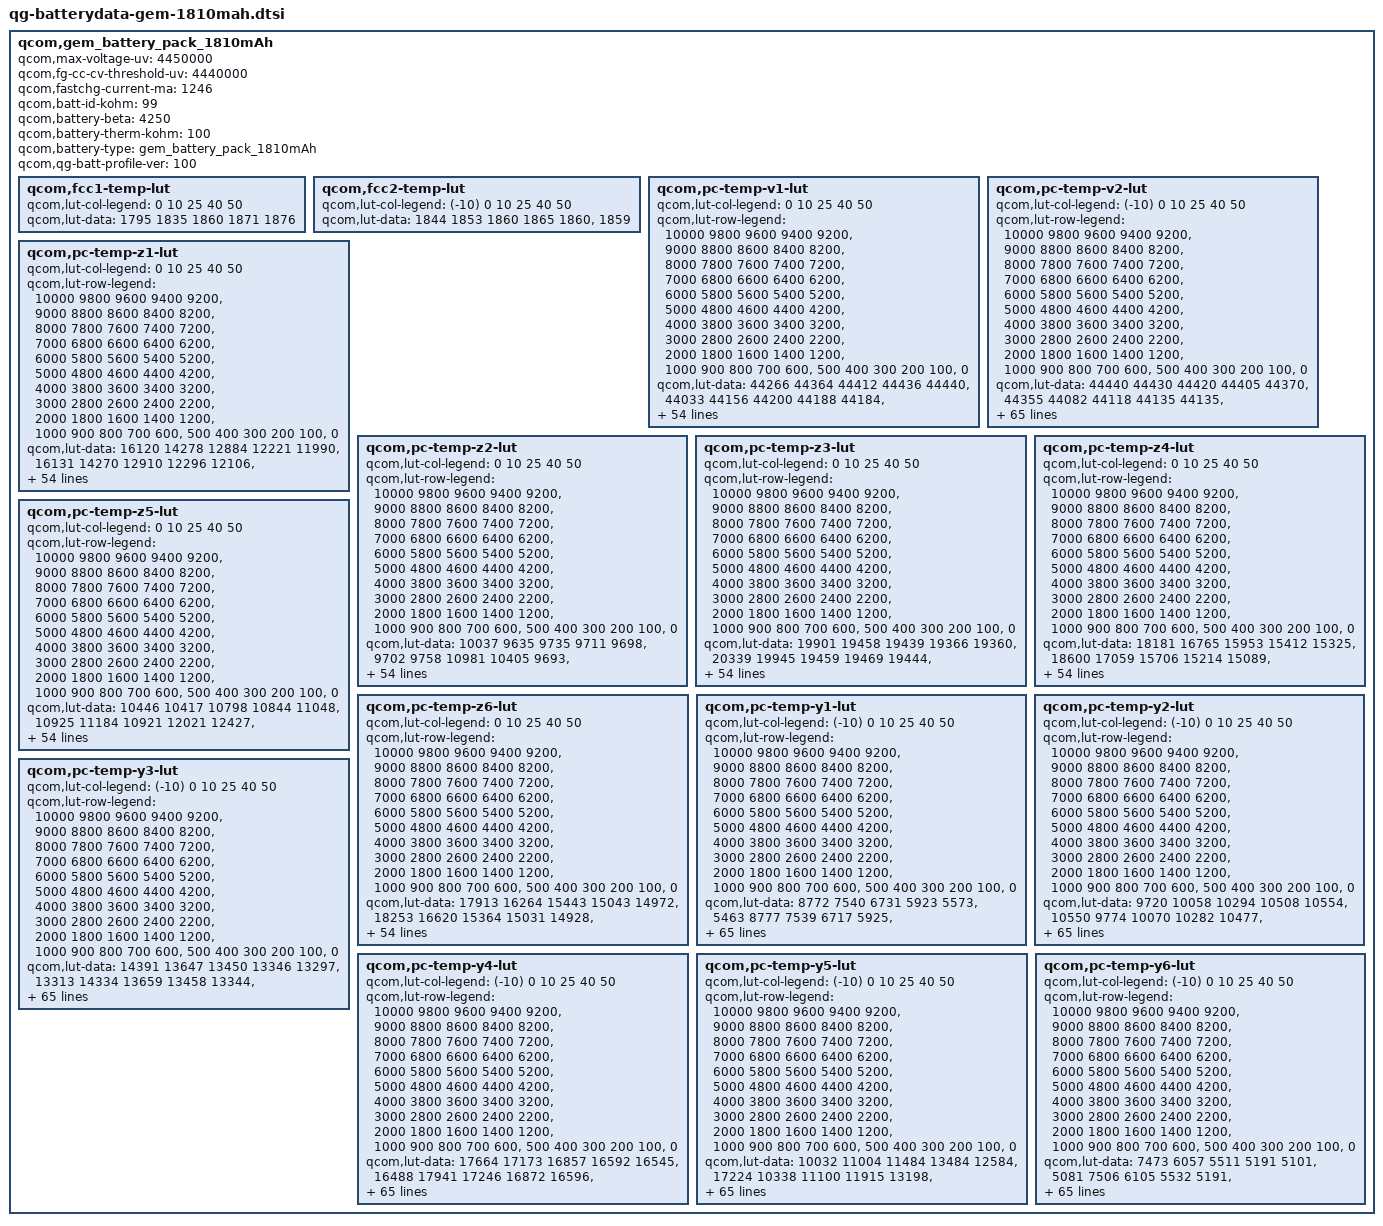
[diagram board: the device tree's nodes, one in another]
qcom,gem_battery_pack_1810mAh {
	qcom,max-voltage-uv = <4450000>;
	qcom,fg-cc-cv-threshold-uv = <4440000>;
	qcom,fastchg-current-ma = <1246>;
	qcom,batt-id-kohm = <99>;
	qcom,battery-beta = <4250>;
	qcom,battery-therm-kohm = <100>;
	qcom,battery-type = "gem_battery_pack_1810mAh";
	qcom,qg-batt-profile-ver = <100>;

	qcom,fcc1-temp-lut {
		qcom,lut-col-legend = <0 10 25 40 50>;
		qcom,lut-data = <1795 1835 1860 1871 1876>;
	};

	qcom,fcc2-temp-lut {
		qcom,lut-col-legend = <(-10) 0 10 25 40 50>;
		qcom,lut-data = <1844 1853 1860 1865 1860>,
			<1859>;
	};

	qcom,pc-temp-v1-lut {
		qcom,lut-col-legend = <0 10 25 40 50>;
		qcom,lut-row-legend = <10000 9800 9600 9400 9200>,
			<9000 8800 8600 8400 8200>,
			<8000 7800 7600 7400 7200>,
			<7000 6800 6600 6400 6200>,
			<6000 5800 5600 5400 5200>,
			<5000 4800 4600 4400 4200>,
			<4000 3800 3600 3400 3200>,
			<3000 2800 2600 2400 2200>,
			<2000 1800 1600 1400 1200>,
			<1000 900 800 700 600>,
			<500 400 300 200 100>,
			<0>;
		qcom,lut-data = <44266 44364 44412 44436 44440>,
			<44033 44156 44200 44188 44184>,
			<43803 43937 43983 43980 43968>,
			<43575 43713 43758 43763 43754>,
			<43350 43485 43530 43540 43536>,
			<43117 43251 43301 43315 43315>,
			<42874 43012 43067 43085 43088>,
			<42630 42765 42822 42847 42853>,
			<42387 42516 42568 42599 42606>,
			<42145 42269 42318 42350 42356>,
			<41909 42023 42072 42099 42109>,
			<41679 41784 41831 41852 41865>,
			<41454 41552 41591 41610 41624>,
			<41235 41325 41356 41375 41384>,
			<41021 41105 41131 41147 41154>,
			<40813 40892 40916 40926 40930>,
			<40611 40687 40709 40713 40716>,
			<40415 40488 40509 40511 40513>,
			<40226 40297 40316 40317 40321>,
			<40044 40117 40133 40130 40133>,
			<39870 39941 39962 39957 39958>,
			<39708 39754 39762 39769 39771>,
			<39549 39560 39472 39526 39539>,
			<39378 39355 39195 39271 39291>,
			<39202 39105 39037 39084 39099>,
			<39030 38875 38924 38938 38944>,
			<38849 38752 38814 38809 38808>,
			<38689 38673 38704 38691 38686>,
			<38585 38598 38599 38584 38576>,
			<38507 38519 38500 38482 38472>,
			<38442 38445 38408 38388 38377>,
			<38382 38373 38328 38303 38290>,
			<38331 38305 38257 38225 38209>,
			<38284 38245 38194 38154 38135>,
			<38243 38194 38140 38093 38070>,
			<38204 38148 38090 38038 38009>,
			<38169 38107 38042 37977 37938>,
			<38132 38069 37996 37913 37855>,
			<38077 38015 37937 37840 37768>,
			<37998 37926 37846 37753 37679>,
			<37903 37819 37735 37652 37582>,
			<37789 37705 37619 37537 37469>,
			<37654 37574 37488 37403 37336>,
			<37485 37413 37328 37247 37178>,
			<37327 37251 37176 37098 37031>,
			<37205 37143 37073 37004 36946>,
			<37182 37109 37051 36984 36923>,
			<37144 37086 37032 36967 36907>,
			<37109 37063 37014 36948 36891>,
			<37059 37018 36966 36887 36815>,
			<36871 36801 36720 36614 36524>,
			<36426 36362 36283 36170 36077>,
			<35839 35770 35703 35591 35497>,
			<35026 34940 34909 34800 34704>,
			<33654 33600 33657 33571 33473>,
			<30000 30000 30000 30000 30000>;
	};

	qcom,pc-temp-v2-lut {
		qcom,lut-col-legend = <(-10) 0 10 25 40 50>;
		qcom,lut-row-legend = <10000 9800 9600 9400 9200>,
			<9000 8800 8600 8400 8200>,
			<8000 7800 7600 7400 7200>,
			<7000 6800 6600 6400 6200>,
			<6000 5800 5600 5400 5200>,
			<5000 4800 4600 4400 4200>,
			<4000 3800 3600 3400 3200>,
			<3000 2800 2600 2400 2200>,
			<2000 1800 1600 1400 1200>,
			<1000 900 800 700 600>,
			<500 400 300 200 100>,
			<0>;
		qcom,lut-data = <44440 44430 44420 44405 44370>,
			<44355 44082 44118 44135 44135>,
			<44100 44087 43764 43834 43871>,
			<43882 43846 43834 43497 43585>,
			<43634 43651 43613 43599 43272>,
			<43369 43421 43440 43399 43381>,
			<43045 43145 43200 43220 43178>,
			<43159 42798 42900 42958 42983>,
			<42942 42924 42547 42648 42709>,
			<42739 42699 42684 42300 42397>,
			<42460 42492 42454 42441 42054>,
			<42144 42210 42242 42206 42194>,
			<41803 41898 41963 41994 41961>,
			<41950 41536 41661 41721 41751>,
			<41718 41708 41272 41427 41483>,
			<41510 41479 41469 41032 41196>,
			<41251 41273 41245 41236 40806>,
			<40966 41026 41042 41018 41007>,
			<40574 40728 40806 40820 40798>,
			<40789 40331 40477 40596 40606>,
			<40586 40580 40088 40228 40377>,
			<40400 40382 40378 39846 39984>,
			<40130 40212 40192 40188 39608>,
			<39747 39873 40024 40006 40001>,
			<39390 39529 39637 39800 39798>,
			<39798 39190 39329 39415 39538>,
			<39568 39578 39001 39145 39215>,
			<39301 39346 39361 38813 38974>,
			<39035 39096 39130 39143 38632>,
			<38817 38874 38916 38933 38941>,
			<38472 38676 38729 38767 38781>,
			<38787 38325 38550 38599 38639>,
			<38655 38662 38208 38419 38480>,
			<38523 38541 38546 38128 38262>,
			<38370 38414 38434 38437 38062>,
			<38117 38268 38313 38335 38335>,
			<37997 38019 38177 38220 38244>,
			<38243 37934 37943 38092 38132>,
			<38159 38156 37871 37882 38004>,
			<38053 38080 38077 37808 37834>,
			<37904 37981 38010 38008 37744>,
			<37790 37820 37911 37934 37930>,
			<37676 37740 37767 37842 37843>,
			<37823 37606 37687 37723 37772>,
			<37743 37698 37532 37629 37671>,
			<37687 37640 37584 37453 37564>,
			<37613 37589 37532 37476 37371>,
			<37491 37544 37493 37431 37376>,
			<37289 37403 37449 37406 37348>,
			<37291 37207 37299 37338 37306>,
			<37256 37199 37136 37176 37213>,
			<37176 37131 37074 37064 37040>,
			<37063 37032 36992 36936 36988>,
			<36911 36908 36901 36862 36810>,
			<36886 36809 36839 36868 36835>,
			<36783 36831 36767 36811 36851>,
			<36822 36772 36773 36726 36780>,
			<36828 36803 36751 36692 36673>,
			<36733 36781 36766 36708 36558>,
			<36580 36594 36621 36623 36549>,
			<36318 36331 36256 36228 36262>,
			<36175 35904 35839 35719 35693>,
			<35744 35651 35287 35136 35004>,
			<34979 35075 34979 34386 34082>,
			<33995 34017 34181 34106 32859>,
			<32571 32496 32755 33007 32869>,
			<30331 28765 28287 28539 28545>,
			<28582>;
	};

	qcom,pc-temp-z1-lut {
		qcom,lut-col-legend = <0 10 25 40 50>;
		qcom,lut-row-legend = <10000 9800 9600 9400 9200>,
			<9000 8800 8600 8400 8200>,
			<8000 7800 7600 7400 7200>,
			<7000 6800 6600 6400 6200>,
			<6000 5800 5600 5400 5200>,
			<5000 4800 4600 4400 4200>,
			<4000 3800 3600 3400 3200>,
			<3000 2800 2600 2400 2200>,
			<2000 1800 1600 1400 1200>,
			<1000 900 800 700 600>,
			<500 400 300 200 100>,
			<0>;
		qcom,lut-data = <16120 14278 12884 12221 11990>,
			<16131 14270 12910 12296 12106>,
			<16124 14291 12898 12284 12108>,
			<16084 14306 12891 12281 12104>,
			<16033 14303 12883 12278 12100>,
			<16034 14299 12874 12274 12097>,
			<16080 14288 12865 12269 12094>,
			<16112 14266 12855 12265 12092>,
			<16082 14246 12844 12262 12091>,
			<16010 14227 12836 12260 12089>,
			<15977 14206 12831 12256 12087>,
			<15972 14200 12827 12253 12085>,
			<15967 14200 12821 12250 12084>,
			<15954 14199 12815 12248 12084>,
			<15935 14190 12813 12247 12084>,
			<15933 14178 12812 12248 12083>,
			<15950 14173 12812 12248 12083>,
			<15966 14169 12813 12248 12084>,
			<15955 14168 12815 12248 12085>,
			<15918 14176 12818 12248 12087>,
			<15902 14188 12821 12251 12089>,
			<15907 14189 12824 12254 12091>,
			<15915 14185 12825 12257 12095>,
			<15935 14187 12827 12262 12099>,
			<15975 14215 12832 12266 12104>,
			<15992 14251 12840 12270 12109>,
			<15993 14266 12849 12275 12114>,
			<15993 14279 12858 12282 12118>,
			<15995 14283 12868 12289 12123>,
			<16004 14266 12877 12296 12128>,
			<16010 14247 12887 12301 12133>,
			<16018 14250 12896 12307 12137>,
			<16026 14265 12905 12312 12141>,
			<16028 14277 12911 12317 12144>,
			<16037 14301 12914 12322 12148>,
			<16044 14325 12917 12327 12152>,
			<16067 14335 12922 12333 12157>,
			<16098 14345 12934 12339 12162>,
			<16124 14349 12942 12344 12166>,
			<16187 14345 12951 12348 12170>,
			<16221 14346 12958 12353 12173>,
			<16145 14356 12962 12357 12176>,
			<16080 14368 12969 12361 12179>,
			<16093 14397 12982 12363 12182>,
			<16175 14392 12996 12366 12185>,
			<16109 14408 12988 12370 12187>,
			<16135 14385 12991 12370 12187>,
			<16105 14358 12988 12373 12189>,
			<16112 14350 13008 12373 12191>,
			<16182 14398 13009 12378 12194>,
			<16185 14412 13020 12386 12202>,
			<16239 14438 13042 12398 12212>,
			<16212 14512 13068 12416 12224>,
			<16267 14576 13106 12442 12245>,
			<16267 14576 13106 12442 12245>,
			<16267 14576 13106 12442 12245>;
	};

	qcom,pc-temp-z2-lut {
		qcom,lut-col-legend = <0 10 25 40 50>;
		qcom,lut-row-legend = <10000 9800 9600 9400 9200>,
			<9000 8800 8600 8400 8200>,
			<8000 7800 7600 7400 7200>,
			<7000 6800 6600 6400 6200>,
			<6000 5800 5600 5400 5200>,
			<5000 4800 4600 4400 4200>,
			<4000 3800 3600 3400 3200>,
			<3000 2800 2600 2400 2200>,
			<2000 1800 1600 1400 1200>,
			<1000 900 800 700 600>,
			<500 400 300 200 100>,
			<0>;
		qcom,lut-data = <10037 9635 9735 9711 9698>,
			<9702 9758 10981 10405 9693>,
			<9512 9662 10485 10513 10609>,
			<9492 9571 9899 10039 10208>,
			<9484 9548 9652 9751 9798>,
			<9483 9527 9636 9872 9898>,
			<9485 9514 9629 10096 10177>,
			<9488 9504 9632 10140 10258>,
			<9486 9499 9642 10120 10259>,
			<9482 9506 9665 10086 10260>,
			<9479 9522 9766 9944 10244>,
			<9479 9535 9858 9786 10220>,
			<9478 9546 9884 9823 10218>,
			<9480 9556 9899 10006 10229>,
			<9485 9563 9901 10106 10246>,
			<9488 9568 9895 10131 10280>,
			<9488 9576 9891 10150 10311>,
			<9489 9587 9907 10180 10190>,
			<9493 9596 9928 10212 9866>,
			<9503 9603 9900 10183 9760>,
			<9510 9609 9784 9926 9771>,
			<9514 9610 9729 9741 9782>,
			<9517 9610 9741 9733 9788>,
			<9521 9610 9754 9729 9797>,
			<9525 9613 9752 9757 9809>,
			<9529 9616 9742 9874 9827>,
			<9534 9616 9742 9930 9835>,
			<9540 9613 9766 9858 9794>,
			<9543 9612 9786 9777 9743>,
			<9545 9619 9763 9764 9738>,
			<9547 9627 9718 9760 9739>,
			<9551 9628 9709 9760 9741>,
			<9556 9628 9714 9777 9751>,
			<9560 9628 9722 9800 9766>,
			<9565 9629 9737 9825 9779>,
			<9569 9632 9755 9854 9795>,
			<9573 9635 9768 9885 9834>,
			<9577 9641 9777 9920 9937>,
			<9583 9648 9790 9943 10002>,
			<9591 9659 9815 9957 10009>,
			<9599 9666 9836 9966 10013>,
			<9605 9666 9836 9966 9992>,
			<9612 9667 9833 9959 9928>,
			<9625 9672 9834 9921 9913>,
			<9717 9711 9844 9901 9904>,
			<9765 9767 9858 9906 9890>,
			<9636 9768 9846 9889 9877>,
			<9607 9821 9838 9878 9868>,
			<9576 9913 9840 9887 9934>,
			<9564 9933 9852 9949 9934>,
			<9525 9905 9896 9844 9778>,
			<9501 9864 9902 9775 9724>,
			<9416 9758 9874 9739 9688>,
			<9345 9655 9820 9702 9656>,
			<9345 9655 9820 9702 9656>,
			<9345 9655 9820 9702 9656>;
	};

	qcom,pc-temp-z3-lut {
		qcom,lut-col-legend = <0 10 25 40 50>;
		qcom,lut-row-legend = <10000 9800 9600 9400 9200>,
			<9000 8800 8600 8400 8200>,
			<8000 7800 7600 7400 7200>,
			<7000 6800 6600 6400 6200>,
			<6000 5800 5600 5400 5200>,
			<5000 4800 4600 4400 4200>,
			<4000 3800 3600 3400 3200>,
			<3000 2800 2600 2400 2200>,
			<2000 1800 1600 1400 1200>,
			<1000 900 800 700 600>,
			<500 400 300 200 100>,
			<0>;
		qcom,lut-data = <19901 19458 19439 19366 19360>,
			<20339 19945 19459 19469 19444>,
			<20618 20081 19643 19544 19529>,
			<20717 20205 19801 19603 19555>,
			<20776 20265 19856 19641 19568>,
			<20793 20308 19839 19667 19581>,
			<20780 20317 19815 19685 19592>,
			<20765 20307 19797 19685 19595>,
			<20762 20290 19781 19667 19595>,
			<20755 20257 19779 19642 19594>,
			<20745 20202 19801 19591 19578>,
			<20717 20156 19820 19542 19553>,
			<20681 20112 19816 19545 19546>,
			<20643 20081 19804 19569 19544>,
			<20602 20066 19785 19578 19542>,
			<20572 20055 19750 19572 19537>,
			<20552 20044 19724 19564 19530>,
			<20533 20032 19716 19558 19496>,
			<20512 20019 19710 19552 19425>,
			<20490 20003 19688 19537 19400>,
			<20483 19990 19638 19484 19399>,
			<20484 19997 19618 19450 19399>,
			<20487 20036 19663 19451 19398>,
			<20506 20070 19712 19453 19396>,
			<20557 20092 19686 19469 19409>,
			<20590 20108 19610 19530 19471>,
			<20607 20095 19587 19561 19508>,
			<20619 20042 19625 19564 19505>,
			<20611 20011 19668 19565 19499>,
			<20575 20002 19696 19562 19492>,
			<20542 19998 19721 19551 19480>,
			<20517 20006 19723 19539 19469>,
			<20495 20030 19705 19529 19459>,
			<20476 20039 19684 19517 19449>,
			<20460 20033 19669 19501 19438>,
			<20444 20023 19656 19486 19427>,
			<20431 20013 19645 19484 19426>,
			<20419 20000 19636 19487 19434>,
			<20403 19988 19629 19489 19441>,
			<20385 19977 19623 19481 19445>,
			<20361 19964 19616 19470 19447>,
			<20321 19949 19608 19466 19441>,
			<20272 19930 19597 19464 19424>,
			<20225 19904 19589 19450 19430>,
			<20023 19847 19569 19439 19431>,
			<19899 19742 19550 19435 19394>,
			<19441 19730 19533 19415 19394>,
			<19423 19590 19529 19410 19394>,
			<19390 19423 19505 19401 19360>,
			<19381 19395 19481 19400 19384>,
			<19384 19483 19440 19438 19428>,
			<19423 19401 19434 19448 19437>,
			<19446 19409 19427 19457 19447>,
			<19487 19718 19433 19466 19447>,
			<19487 19718 19433 19466 19447>,
			<19487 19718 19433 19466 19447>;
	};

	qcom,pc-temp-z4-lut {
		qcom,lut-col-legend = <0 10 25 40 50>;
		qcom,lut-row-legend = <10000 9800 9600 9400 9200>,
			<9000 8800 8600 8400 8200>,
			<8000 7800 7600 7400 7200>,
			<7000 6800 6600 6400 6200>,
			<6000 5800 5600 5400 5200>,
			<5000 4800 4600 4400 4200>,
			<4000 3800 3600 3400 3200>,
			<3000 2800 2600 2400 2200>,
			<2000 1800 1600 1400 1200>,
			<1000 900 800 700 600>,
			<500 400 300 200 100>,
			<0>;
		qcom,lut-data = <18181 16765 15953 15412 15325>,
			<18600 17059 15706 15214 15089>,
			<18728 16810 15852 15326 15129>,
			<18454 16499 15625 15255 15092>,
			<17773 16228 15433 15156 15033>,
			<17275 15950 15306 15047 14970>,
			<16952 15746 15212 14936 14899>,
			<16685 15591 15163 14902 14857>,
			<16452 15473 15131 14890 14832>,
			<16250 15383 15084 14886 14819>,
			<16077 15313 14999 14916 14816>,
			<15925 15283 14927 14955 14814>,
			<15797 15271 14893 14939 14807>,
			<15696 15257 14870 14867 14785>,
			<15612 15230 14866 14821 14765>,
			<15560 15196 14865 14802 14747>,
			<15530 15174 14865 14788 14735>,
			<15507 15158 14850 14767 14756>,
			<15487 15143 14829 14748 14814>,
			<15470 15126 14833 14748 14833>,
			<15446 15112 14868 14787 14826>,
			<15398 15112 14926 14851 14820>,
			<15355 15121 15107 15006 14922>,
			<15344 15139 15287 15186 15101>,
			<15338 15287 15323 15196 15122>,
			<15339 15462 15339 15125 15049>,
			<15418 15473 15335 15059 14985>,
			<15509 15438 15250 15011 14952>,
			<15517 15397 15146 14970 14927>,
			<15511 15350 15072 14938 14903>,
			<15501 15299 15008 14910 14882>,
			<15477 15245 14981 14888 14863>,
			<15443 15190 14970 14868 14842>,
			<15412 15158 14962 14858 14830>,
			<15380 15142 14956 14857 14828>,
			<15350 15131 14952 14858 14828>,
			<15320 15121 14953 14864 14835>,
			<15293 15113 14960 14893 14876>,
			<15272 15112 14970 14915 14901>,
			<15255 15126 14997 14925 14891>,
			<15237 15139 15021 14931 14873>,
			<15215 15117 15010 14922 14860>,
			<15186 15070 14978 14896 14850>,
			<15136 15037 14965 14904 14845>,
			<15073 14965 14936 14902 14840>,
			<15046 14921 14860 14844 14822>,
			<15528 14905 14840 14829 14793>,
			<15535 15028 14805 14788 14745>,
			<15548 15181 14791 14753 14739>,
			<15530 15195 14811 14770 14732>,
			<15529 15127 14910 14773 14726>,
			<15557 15241 14919 14770 14721>,
			<15586 15257 14927 14757 14713>,
			<15629 14961 14926 14750 14717>,
			<15629 14961 14926 14750 14717>,
			<15629 14961 14926 14750 14717>;
	};

	qcom,pc-temp-z5-lut {
		qcom,lut-col-legend = <0 10 25 40 50>;
		qcom,lut-row-legend = <10000 9800 9600 9400 9200>,
			<9000 8800 8600 8400 8200>,
			<8000 7800 7600 7400 7200>,
			<7000 6800 6600 6400 6200>,
			<6000 5800 5600 5400 5200>,
			<5000 4800 4600 4400 4200>,
			<4000 3800 3600 3400 3200>,
			<3000 2800 2600 2400 2200>,
			<2000 1800 1600 1400 1200>,
			<1000 900 800 700 600>,
			<500 400 300 200 100>,
			<0>;
		qcom,lut-data = <10446 10417 10798 10844 11048>,
			<10925 11184 10921 12021 12427>,
			<11250 11546 11567 11950 12830>,
			<11393 11917 12546 12577 13393>,
			<11485 12192 13051 13442 14033>,
			<11577 12426 13167 14463 14628>,
			<11669 12631 13251 15497 15216>,
			<11767 12857 13363 15662 15796>,
			<11894 13051 13526 15490 16461>,
			<12060 13265 13815 15213 16813>,
			<12226 13504 14583 14403 16446>,
			<12386 13536 15410 13547 15866>,
			<12550 13420 16033 13738 15911>,
			<12729 13337 16535 14758 16614>,
			<12917 13472 16536 15580 17377>,
			<13082 13746 15989 16048 18213>,
			<13224 13935 15641 16511 18826>,
			<13349 14105 16006 17284 17589>,
			<13445 14269 16522 18154 14226>,
			<13524 14392 16353 18077 13149>,
			<13659 14536 15440 15978 13452>,
			<13988 15194 15074 14167 13695>,
			<14534 17225 17373 13594 13189>,
			<15646 18682 19880 13243 12299>,
			<17639 19305 18512 13144 12199>,
			<19107 19683 14423 13126 12609>,
			<20134 19005 13034 13171 12999>,
			<20813 16505 13160 13436 13306>,
			<20484 15158 13404 13849 13599>,
			<19081 14922 14193 14273 13828>,
			<18033 14806 15544 14772 14125>,
			<17503 15166 16347 15336 14481>,
			<17170 16334 16828 16071 14988>,
			<17109 17191 17218 16638 15449>,
			<17094 17710 17631 16903 15743>,
			<17099 18064 17942 17081 15962>,
			<17193 18193 17944 17100 16008>,
			<17375 18194 17762 17029 15927>,
			<17661 18158 17489 16893 15851>,
			<18159 18025 16788 15932 15772>,
			<18401 17849 16047 14774 15625>,
			<17660 17657 15810 14612 15238>,
			<16997 17402 15673 14595 14544>,
			<17071 17032 15319 13932 14463>,
			<15975 17246 15226 13480 14252>,
			<14909 15719 16331 14088 13310>,
			<10827 15212 15712 13722 13726>,
			<10745 13413 16227 14241 14996>,
			<10632 11075 15384 15047 14095>,
			<10613 10868 14283 14185 14929>,
			<10639 11441 12232 14171 15900>,
			<10671 10831 11880 14237 16341>,
			<10643 10793 11679 14657 17464>,
			<10660 13443 11676 15192 17310>,
			<10660 13443 11676 15192 17310>,
			<10660 13443 11676 15192 17310>;
	};

	qcom,pc-temp-z6-lut {
		qcom,lut-col-legend = <0 10 25 40 50>;
		qcom,lut-row-legend = <10000 9800 9600 9400 9200>,
			<9000 8800 8600 8400 8200>,
			<8000 7800 7600 7400 7200>,
			<7000 6800 6600 6400 6200>,
			<6000 5800 5600 5400 5200>,
			<5000 4800 4600 4400 4200>,
			<4000 3800 3600 3400 3200>,
			<3000 2800 2600 2400 2200>,
			<2000 1800 1600 1400 1200>,
			<1000 900 800 700 600>,
			<500 400 300 200 100>,
			<0>;
		qcom,lut-data = <17913 16264 15443 15043 14972>,
			<18253 16620 15364 15031 14928>,
			<18389 16557 15486 15109 14992>,
			<18271 16463 15466 15102 14984>,
			<17966 16368 15438 15090 14971>,
			<17729 16254 15378 15065 14953>,
			<17560 16157 15312 15028 14929>,
			<17414 16076 15278 15004 14913>,
			<17292 16004 15255 14989 14904>,
			<17186 15936 15231 14975 14895>,
			<17087 15876 15207 14963 14883>,
			<16992 15834 15185 14951 14871>,
			<16908 15804 15168 14937 14860>,
			<16836 15779 15152 14922 14850>,
			<16774 15754 15135 14909 14840>,
			<16734 15733 15118 14897 14831>,
			<16709 15714 15102 14886 14821>,
			<16690 15698 15089 14874 14809>,
			<16671 15684 15078 14862 14796>,
			<16654 15669 15071 14855 14788>,
			<16638 15657 15066 14851 14785>,
			<16619 15660 15067 14849 14783>,
			<16606 15682 15168 14907 14827>,
			<16613 15716 15278 14995 14905>,
			<16640 15798 15278 15009 14921>,
			<16672 15882 15254 15008 14921>,
			<16719 15882 15233 15006 14920>,
			<16760 15846 15217 14992 14909>,
			<16760 15814 15202 14971 14892>,
			<16746 15790 15188 14954 14877>,
			<16729 15771 15175 14938 14862>,
			<16709 15758 15162 14923 14848>,
			<16688 15748 15150 14909 14834>,
			<16668 15739 15138 14897 14822>,
			<16649 15732 15128 14888 14814>,
			<16634 15726 15119 14881 14807>,
			<16623 15720 15118 14882 14810>,
			<16614 15714 15117 14898 14833>,
			<16606 15713 15117 14907 14847>,
			<16599 15718 15126 14906 14844>,
			<16590 15723 15136 14905 14839>,
			<16573 15713 15130 14900 14830>,
			<16549 15689 15112 14888 14817>,
			<16520 15671 15103 14885 14819>,
			<16405 15622 15083 14879 14819>,
			<16338 15560 15044 14852 14791>,
			<16314 15547 15026 14836 14778>,
			<16307 15532 15010 14815 14759>,
			<16305 15515 14991 14794 14735>,
			<16308 15518 14993 14800 14746>,
			<16334 15548 15018 14826 14770>,
			<16389 15569 15025 14833 14776>,
			<16448 15603 15032 14836 14781>,
			<16537 15671 15048 14844 14788>,
			<16537 15671 15048 14844 14788>,
			<16537 15671 15048 14844 14788>;
	};

	qcom,pc-temp-y1-lut {
		qcom,lut-col-legend = <(-10) 0 10 25 40 50>;
		qcom,lut-row-legend = <10000 9800 9600 9400 9200>,
			<9000 8800 8600 8400 8200>,
			<8000 7800 7600 7400 7200>,
			<7000 6800 6600 6400 6200>,
			<6000 5800 5600 5400 5200>,
			<5000 4800 4600 4400 4200>,
			<4000 3800 3600 3400 3200>,
			<3000 2800 2600 2400 2200>,
			<2000 1800 1600 1400 1200>,
			<1000 900 800 700 600>,
			<500 400 300 200 100>,
			<0>;
		qcom,lut-data = <8772 7540 6731 5923 5573>,
			<5463 8777 7539 6717 5925>,
			<5570 5462 8778 7536 6698>,
			<5924 5566 5460 8775 7533>,
			<6680 5920 5563 5459 8770>,
			<7530 6665 5914 5560 5457>,
			<8764 7529 6659 5908 5558>,
			<5456 8743 7528 6658 5898>,
			<5556 5456 8720 7528 6659>,
			<5888 5554 5455 8733 7531>,
			<6655 5881 5552 5454 8782>,
			<7541 6642 5875 5549 5453>,
			<8804 7548 6638 5871 5546>,
			<5451 8790 7535 6640 5867>,
			<5543 5449 8769 7519 6642>,
			<5865 5541 5448 8753 7520>,
			<6633 5864 5540 5448 8737>,
			<7523 6616 5862 5540 5448>,
			<8734 7523 6612 5862 5540>,
			<5448 8746 7511 6618 5861>,
			<5539 5448 8762 7502 6625>,
			<5860 5539 5448 8794 7516>,
			<6636 5861 5539 5448 8847>,
			<7542 6650 5862 5540 5448>,
			<8856 7552 6652 5864 5540>,
			<5449 8807 7568 6649 5866>,
			<5542 5449 8770 7573 6647>,
			<5869 5544 5450 8800 7548>,
			<6640 5870 5546 5452 8855>,
			<7517 6633 5873 5548 5454>,
			<8852 7514 6634 5876 5550>,
			<5455 8764 7518 6641 5881>,
			<5551 5456 8708 7523 6648>,
			<5886 5553 5458 8719 7535>,
			<6655 5891 5557 5460 8735>,
			<7547 6660 5896 5562 5464>,
			<8731 7540 6658 5900 5565>,
			<5467 8702 7518 6653 5903>,
			<5568 5470 8687 7509 6654>,
			<5908 5572 5473 8723 7511>,
			<6664 5914 5576 5477 8767>,
			<7514 6674 5921 5581 5480>,
			<8756 7522 6680 5926 5585>,
			<5482 8707 7539 6684 5932>,
			<5588 5485 8686 7543 6687>,
			<5938 5591 5487 8693 7539>,
			<6697 5946 5593 5489 8707>,
			<7532 6704 5950 5595 5492>,
			<8733 7513 6698 5952 5598>,
			<5495 8760 7496 6694 5955>,
			<5601 5497 8758 7526 6688>,
			<5965 5604 5497 8732 7543>,
			<6726 5974 5607 5500 8727>,
			<7584 6718 5971 5609 5504>,
			<8915 7558 6710 5979 5613>,
			<5506 8867 7606 6708 5984>,
			<5614 5507 8827 7601 6741>,
			<5990 5614 5508 8823 7567>,
			<6727 5984 5617 5507 8870>,
			<7603 6719 6002 5618 5509>,
			<9052 7591 6730 6003 5623>,
			<5513 9204 7666 6737 6016>,
			<5632 5521 9381 7797 6791>,
			<6038 5642 5532 9595 7935>,
			<6897 6080 5659 5545 9595>,
			<7935 6897 6080 5659 5545>,
			<9595 7935 6897 6080 5659>,
			<5545>;
	};

	qcom,pc-temp-y2-lut {
		qcom,lut-col-legend = <(-10) 0 10 25 40 50>;
		qcom,lut-row-legend = <10000 9800 9600 9400 9200>,
			<9000 8800 8600 8400 8200>,
			<8000 7800 7600 7400 7200>,
			<7000 6800 6600 6400 6200>,
			<6000 5800 5600 5400 5200>,
			<5000 4800 4600 4400 4200>,
			<4000 3800 3600 3400 3200>,
			<3000 2800 2600 2400 2200>,
			<2000 1800 1600 1400 1200>,
			<1000 900 800 700 600>,
			<500 400 300 200 100>,
			<0>;
		qcom,lut-data = <9720 10058 10294 10508 10554>,
			<10550 9774 10070 10282 10477>,
			<10510 10516 9826 10087 10270>,
			<10445 10463 10477 9875 10104>,
			<10258 10416 10421 10440 9917>,
			<10117 10249 10391 10391 10409>,
			<9950 10121 10240 10374 10382>,
			<10388 9976 10118 10231 10363>,
			<10393 10371 9997 10115 10225>,
			<10355 10405 10361 10013 10116>,
			<10224 10349 10405 10367 10026>,
			<10118 10224 10344 10400 10388>,
			<10041 10122 10225 10342 10398>,
			<10398 10062 10129 10230 10347>,
			<10396 10396 10083 10140 10237>,
			<10355 10396 10396 10096 10162>,
			<10242 10367 10404 10404 10105>,
			<10195 10247 10385 10422 10420>,
			<10119 10213 10258 10403 10437>,
			<10437 10146 10219 10282 10423>,
			<10451 10455 10167 10226 10303>,
			<10443 10469 10475 10167 10238>,
			<10313 10468 10503 10495 10165>,
			<10251 10320 10489 10546 10517>,
			<10149 10261 10329 10488 10575>,
			<10552 10034 10267 10340 10474>,
			<10599 10615 9939 10272 10350>,
			<10467 10608 10644 9850 10275>,
			<10358 10477 10562 10585 9707>,
			<10277 10366 10492 10508 10513>,
			<9670 10275 10373 10505 10513>,
			<10515 9666 10265 10381 10518>,
			<10549 10546 9663 10253 10383>,
			<10532 10586 10564 9660 10239>,
			<10383 10547 10625 10569 9658>,
			<10225 10382 10560 10663 10575>,
			<9657 10218 10371 10573 10690>,
			<10609 9656 10213 10350 10584>,
			<10713 10682 9655 10203 10343>,
			<10588 10742 10744 9654 10177>,
			<10346 10590 10782 10806 9653>,
			<10132 10347 10590 10805 10839>,
			<9653 9984 10339 10577 10792>,
			<10806 9653 9744 10321 10554>,
			<10761 10741 9653 9671 10302>,
			<10538 10718 10707 9653 9663>,
			<10279 10524 10646 10687 9653>,
			<9659 10255 10512 10603 10665>,
			<9652 9657 10234 10504 10615>,
			<10622 9652 9655 10209 10495>,
			<10624 10599 9652 9654 10173>,
			<10483 10582 10598 9652 9653>,
			<10144 10466 10614 10617 9651>,
			<9653 10164 10449 10553 10579>,
			<9651 9652 10103 10426 10485>,
			<10473 9651 9651 10071 10424>,
			<10466 10423 9650 9651 10044>,
			<10415 10456 10394 9650 9650>,
			<10017 10402 10472 10422 9649>,
			<9650 9819 10385 10465 10421>,
			<9647 9649 9687 10363 10440>,
			<10379 9647 9648 9660 10320>,
			<10425 10350 9646 9647 9652>,
			<10273 10384 10314 9646 9647>,
			<9648 10241 10345 10303 9646>,
			<9647 9648 10241 10345 10303>,
			<9646 9647 9648 10241 10345>,
			<10303>;
	};

	qcom,pc-temp-y3-lut {
		qcom,lut-col-legend = <(-10) 0 10 25 40 50>;
		qcom,lut-row-legend = <10000 9800 9600 9400 9200>,
			<9000 8800 8600 8400 8200>,
			<8000 7800 7600 7400 7200>,
			<7000 6800 6600 6400 6200>,
			<6000 5800 5600 5400 5200>,
			<5000 4800 4600 4400 4200>,
			<4000 3800 3600 3400 3200>,
			<3000 2800 2600 2400 2200>,
			<2000 1800 1600 1400 1200>,
			<1000 900 800 700 600>,
			<500 400 300 200 100>,
			<0>;
		qcom,lut-data = <14391 13647 13450 13346 13297>,
			<13313 14334 13659 13458 13344>,
			<13300 13304 14280 13675 13469>,
			<13345 13303 13299 14230 13690>,
			<13480 13346 13306 13297 14186>,
			<13701 13489 13347 13310 13296>,
			<14151 13704 13491 13350 13313>,
			<13296 14124 13703 13490 13353>,
			<13317 13300 14101 13700 13488>,
			<13357 13321 13306 14076 13695>,
			<13487 13359 13324 13311 14050>,
			<13689 13486 13361 13326 13317>,
			<14019 13685 13485 13363 13328>,
			<13320 13976 13683 13483 13367>,
			<13328 13321 13931 13681 13482>,
			<13371 13329 13322 13893 13677>,
			<13483 13370 13335 13323 13859>,
			<13671 13486 13369 13343 13323>,
			<13838 13661 13489 13368 13345>,
			<13324 13827 13637 13496 13367>,
			<13340 13330 13816 13614 13500>,
			<13366 13336 13334 13787 13603>,
			<13490 13371 13335 13331 13742>,
			<13594 13472 13378 13334 13325>,
			<13712 13582 13459 13377 13332>,
			<13323 13690 13563 13448 13368>,
			<13328 13319 13678 13548 13440>,
			<13358 13323 13315 13691 13540>,
			<13432 13347 13313 13306 13714>,
			<13534 13426 13339 13304 13296>,
			<13717 13529 13423 13336 13304>,
			<13295 13703 13526 13421 13334>,
			<13306 13297 13694 13522 13420>,
			<13334 13307 13297 13716 13515>,
			<13419 13336 13307 13296 13764>,
			<13506 13418 13337 13308 13296>,
			<13823 13489 13419 13337 13308>,
			<13296 13908 13462 13422 13337>,
			<13308 13296 14000 13455 13422>,
			<13337 13309 13297 14097 13472>,
			<13418 13336 13313 13300 14197>,
			<13500 13414 13336 13315 13301>,
			<14290 13537 13418 13339 13312>,
			<13299 14379 13589 13426 13343>,
			<13307 13295 14462 13644 13434>,
			<13342 13302 13293 14538 13706>,
			<13442 13339 13297 13290 14608>,
			<13773 13447 13337 13295 13289>,
			<14669 13846 13450 13338 13299>,
			<13291 14727 13928 13451 13339>,
			<13301 13293 14813 14028 13451>,
			<13334 13300 13295 14904 14119>,
			<13451 13334 13300 13294 14810>,
			<13982 13421 13325 13294 13287>,
			<14978 14255 13441 13339 13306>,
			<13299 15182 14431 13456 13343>,
			<13310 13306 15461 14679 13476>,
			<13348 13317 13307 15836 14931>,
			<13506 13361 13329 13313 16652>,
			<15214 13537 13367 13324 13311>,
			<18805 15584 13626 13366 13320>,
			<13309 23816 16611 13861 13379>,
			<13325 13312 37048 20370 14567>,
			<13392 13332 13317 65535 33347>,
			<16828 13423 13339 13324 65535>,
			<33347 16828 13423 13339 13324>,
			<65535 33347 16828 13423 13339>,
			<13324>;
	};

	qcom,pc-temp-y4-lut {
		qcom,lut-col-legend = <(-10) 0 10 25 40 50>;
		qcom,lut-row-legend = <10000 9800 9600 9400 9200>,
			<9000 8800 8600 8400 8200>,
			<8000 7800 7600 7400 7200>,
			<7000 6800 6600 6400 6200>,
			<6000 5800 5600 5400 5200>,
			<5000 4800 4600 4400 4200>,
			<4000 3800 3600 3400 3200>,
			<3000 2800 2600 2400 2200>,
			<2000 1800 1600 1400 1200>,
			<1000 900 800 700 600>,
			<500 400 300 200 100>,
			<0>;
		qcom,lut-data = <17664 17173 16857 16592 16545>,
			<16488 17941 17246 16872 16596>,
			<16541 16501 18199 17356 16895>,
			<16599 16536 16508 18413 17472>,
			<16917 16603 16531 16512 18556>,
			<17562 16935 16607 16527 16514>,
			<18602 17592 16940 16610 16525>,
			<16515 18546 17582 16938 16613>,
			<16525 16512 18457 17568 16935>,
			<16617 16525 16508 18400 17565>,
			<16937 16624 16527 16507 18357>,
			<17563 16946 16636 16535 16504>,
			<18312 17563 16957 16648 16545>,
			<16506 18261 17562 16979 16661>,
			<16560 16514 18211 17559 17004>,
			<16675 16573 16524 18171 17554>,
			<17026 16697 16578 16537 18137>,
			<17541 17047 16730 16582 16551>,
			<18078 17523 17060 16764 16593>,
			<16564 17937 17486 17071 16807>,
			<16626 16573 17786 17436 17075>,
			<16845 16666 16585 17687 17355>,
			<17040 16882 16713 16621 17607>,
			<17256 16968 16909 16755 16664>,
			<17554 17201 16910 16885 16754>,
			<16670 17512 17170 16854 16773>,
			<16719 16661 17476 17140 16817>,
			<16686 16675 16647 17420 17105>,
			<16795 16634 16610 16593 17347>,
			<17069 16781 16603 16555 16537>,
			<17304 17039 16777 16604 16551>,
			<16532 17272 17014 16775 16612>,
			<16552 16532 17258 16975 16775>,
			<16620 16554 16534 17271 16870>,
			<16779 16631 16567 16548 17291>,
			<16774 16783 16645 16588 16567>,
			<17295 16786 16782 16661 16609>,
			<16584 17292 16847 16777 16680>,
			<16632 16603 17290 16889 16764>,
			<16701 16649 16622 17297 16908>,
			<16719 16725 16663 16643 17305>,
			<16929 16687 16737 16670 16655>,
			<17305 16992 16701 16729 16656>,
			<16629 17301 17088 16734 16712>,
			<16628 16580 17297 17136 16769>,
			<16683 16600 16556 17288 17160>,
			<16812 16632 16567 16541 17282>,
			<17170 16834 16612 16553 16535>,
			<17291 17166 16838 16617 16560>,
			<16540 17317 17155 16839 16621>,
			<16565 16543 17343 17115 16839>,
			<16621 16558 16531 17360 17075>,
			<16810 16609 16549 16521 17267>,
			<16991 16716 16552 16505 16490>,
			<17265 17005 16751 16571 16522>,
			<16508 17292 17042 16783 16600>,
			<16546 16522 17314 17090 16832>,
			<16641 16568 16549 17344 17159>,
			<16891 16668 16585 16580 17433>,
			<17226 16997 16651 16567 16544>,
			<17827 17229 17025 16610 16528>,
			<16510 18876 17261 17087 16642>,
			<16534 16518 23625 18318 17273>,
			<16720 16581 16568 56288 27061>,
			<18370 16984 16759 16780 56288>,
			<27061 18370 16984 16759 16780>,
			<56288 27061 18370 16984 16759>,
			<16780>;
	};

	qcom,pc-temp-y5-lut {
		qcom,lut-col-legend = <(-10) 0 10 25 40 50>;
		qcom,lut-row-legend = <10000 9800 9600 9400 9200>,
			<9000 8800 8600 8400 8200>,
			<8000 7800 7600 7400 7200>,
			<7000 6800 6600 6400 6200>,
			<6000 5800 5600 5400 5200>,
			<5000 4800 4600 4400 4200>,
			<4000 3800 3600 3400 3200>,
			<3000 2800 2600 2400 2200>,
			<2000 1800 1600 1400 1200>,
			<1000 900 800 700 600>,
			<500 400 300 200 100>,
			<0>;
		qcom,lut-data = <10032 11004 11484 13484 12584>,
			<17224 10338 11100 11915 13198>,
			<12683 15604 10628 11227 12177>,
			<12884 12841 14251 10901 11359>,
			<12311 12582 13011 13222 11150>,
			<11466 12360 12333 13148 12574>,
			<11373 11521 12364 12174 13204>,
			<12371 11575 11546 12217 12091>,
			<13216 12779 11753 11561 12000>,
			<12017 13219 13273 11913 11561>,
			<11856 11895 13146 13476 12065>,
			<11558 11729 11736 12894 13915>,
			<12116 11571 11660 11629 12617>,
			<13974 12053 11745 11606 11584>,
			<12252 13640 11985 12005 11572>,
			<11575 12006 13223 12061 12262>,
			<11677 11464 12150 12785 12349>,
			<12542 11996 11247 12463 12356>,
			<12721 12721 12478 11208 12456>,
			<12279 13383 12839 13475 11250>,
			<11838 12423 13870 12959 14144>,
			<11330 11404 12526 13771 13200>,
			<14235 12081 11420 12200 13479>,
			<13494 14284 13327 11466 11687>,
			<13254 13580 14247 14224 11855>,
			<11858 13125 13572 14037 15022>,
			<13309 13021 13081 13586 13834>,
			<15278 14055 13641 12744 13747>,
			<13663 14405 13662 13437 12038>,
			<14047 13542 13335 13154 13162>,
			<11537 14498 13563 12976 13025>,
			<13068 10917 15214 13683 12760>,
			<12974 12995 10555 15510 13827>,
			<12723 12906 12869 10506 15068>,
			<13996 12863 12744 12436 10480>,
			<14270 14248 12996 12613 12059>,
			<10505 13142 14974 13021 12599>,
			<12031 10628 11598 16084 13037>,
			<12613 12041 10737 11113 16263>,
			<13090 12730 12098 10820 11470>,
			<15382 13288 13364 12381 10906>,
			<11795 14650 13610 13814 12705>,
			<10987 11665 14534 14626 13793>,
			<12984 11071 11365 14477 15760>,
			<13734 13217 11113 11297 14372>,
			<15706 13601 13239 11113 11407>,
			<14150 14921 13254 13149 11088>,
			<11500 13884 14274 12992 13048>,
			<10958 11490 13502 13904 12915>,
			<12915 10748 11464 13171 13444>,
			<12896 12853 10778 11436 12888>,
			<12611 12500 13089 10809 11238>,
			<12945 12861 12706 13503 10911>,
			<11122 12394 13107 13409 13399>,
			<10863 11084 12387 13412 13356>,
			<13251 10914 10984 12362 12751>,
			<12572 13343 11167 11045 12377>,
			<12227 12487 12582 11267 11068>,
			<12454 12462 13329 12788 11182>,
			<11187 11754 13325 13360 13607>,
			<10544 11164 11465 14661 14297>,
			<15139 9712 10919 11313 16368>,
			<15982 15784 9116 9975 11313>,
			<16308 17085 16998 8831 9122>,
			<10527 16482 17253 17478 8831>,
			<9122 10527 16482 17253 17478>,
			<8831 9122 10527 16482 17253>,
			<17478>;
	};

	qcom,pc-temp-y6-lut {
		qcom,lut-col-legend = <(-10) 0 10 25 40 50>;
		qcom,lut-row-legend = <10000 9800 9600 9400 9200>,
			<9000 8800 8600 8400 8200>,
			<8000 7800 7600 7400 7200>,
			<7000 6800 6600 6400 6200>,
			<6000 5800 5600 5400 5200>,
			<5000 4800 4600 4400 4200>,
			<4000 3800 3600 3400 3200>,
			<3000 2800 2600 2400 2200>,
			<2000 1800 1600 1400 1200>,
			<1000 900 800 700 600>,
			<500 400 300 200 100>,
			<0>;
		qcom,lut-data = <7473 6057 5511 5191 5101>,
			<5081 7506 6105 5532 5191>,
			<5101 5080 7516 6140 5544>,
			<5192 5102 5080 7508 6165>,
			<5551 5193 5103 5080 7487>,
			<6178 5554 5195 5104 5080>,
			<7458 6182 5554 5197 5106>,
			<5081 7412 6171 5548 5199>,
			<5109 5083 7356 6154 5539>,
			<5202 5112 5087 7309 6140>,
			<5534 5205 5115 5090 7267>,
			<6126 5530 5209 5118 5093>,
			<7222 6115 5529 5213 5122>,
			<5096 7170 6106 5530 5219>,
			<5126 5100 7121 6098 5532>,
			<5225 5131 5103 7088 6091>,
			<5535 5231 5136 5107 7061>,
			<6085 5540 5239 5142 5111>,
			<7031 6074 5544 5247 5148>,
			<5116 6995 6049 5551 5257>,
			<5154 5122 6958 6019 5554>,
			<5268 5162 5128 6922 5989>,
			<5537 5282 5173 5137 6888>,
			<5959 5505 5294 5184 5145>,
			<6865 5938 5479 5286 5184>,
			<5145 6848 5923 5456 5248>,
			<5170 5139 6836 5913 5440>,
			<5216 5153 5131 6825 5907>,
			<5430 5193 5127 5108 6811>,
			<5904 5423 5179 5105 5085>,
			<6808 5905 5423 5178 5104>,
			<5083 6809 5911 5424 5180>,
			<5105 5084 6811 5914 5426>,
			<5182 5107 5085 6847 5898>,
			<5430 5187 5111 5089 6920>,
			<5880 5434 5193 5118 5093>,
			<6995 5887 5439 5198 5124>,
			<5099 7084 5918 5445 5204>,
			<5131 5105 7174 5960 5445>,
			<5211 5137 5111 7264 6027>,
			<5436 5219 5144 5119 7351>,
			<6111 5429 5223 5148 5123>,
			<7431 6202 5441 5223 5142>,
			<5115 7505 6303 5467 5222>,
			<5131 5099 7570 6404 5495>,
			<5216 5120 5090 7625 6505>,
			<5528 5200 5108 5084 7677>,
			<6606 5560 5193 5102 5082>,
			<7733 6705 5588 5198 5107>,
			<5085 7794 6803 5614 5200>,
			<5111 5087 7874 6901 5644>,
			<5199 5108 5086 7961 6987>,
			<5652 5197 5106 5083 7892>,
			<6853 5575 5175 5090 5069>,
			<8046 7113 5652 5192 5104>,
			<5084 8222 7279 5710 5204>,
			<5113 5093 8457 7497 5786>,
			<5221 5124 5102 8788 7726>,
			<5885 5239 5139 5115 9521>,
			<7979 6003 5239 5130 5103>,
			<11426 8284 6164 5230 5116>,
			<5093 15609 9134 6494 5254>,
			<5122 5098 26551 12412 7245>,
			<5292 5143 5118 60671 24112>,
			<9422 5404 5202 5186 60671>,
			<24112 9422 5404 5202 5186>,
			<60671 24112 9422 5404 5202>,
			<5186>;
	};
};
